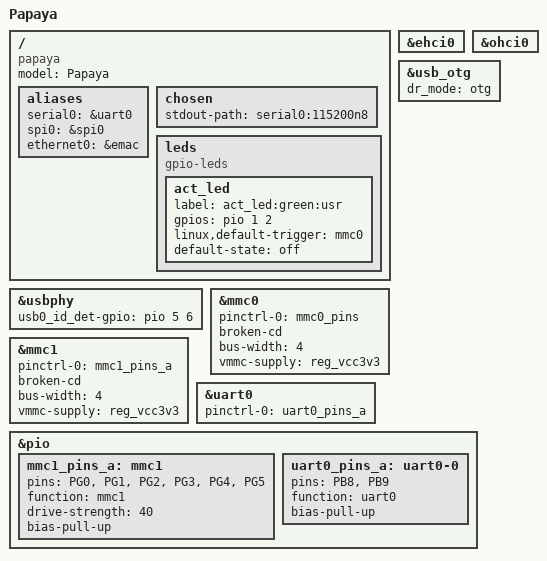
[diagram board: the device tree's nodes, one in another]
/dts-v1/;
#include "sun8i-v3s.dtsi"
#include "sunxi-common-regulators.dtsi"
#include <dt-bindings/input/input.h>
/ {

	model = "Papaya";
	compatible = "papaya", "allwinner,sun8i-v3s";
	
	aliases {
		serial0 = &uart0;
		spi0 = &spi0;
		ethernet0 = &emac;
		
	};
	chosen {
		stdout-path = "serial0:115200n8";
		};

	leds {
	compatible = "gpio-leds";
	act_led {
		label = "act_led:green:usr";
		gpios = <&pio 1 2 GPIO_ACTIVE_HIGH>; /* PB2 */
		linux,default-trigger = "mmc0";
		default-state = "off";
	};
	};
};


&ehci0 {
        status = "okay";
}; 

&ohci0 {
        status = "okay";
}; 

&usb_otg {
	dr_mode = "otg";
	status = "okay";
};

&usbphy {
	usb0_id_det-gpio = <&pio 5 6 GPIO_ACTIVE_HIGH>;
	status = "okay";
};

&mmc0 {
	pinctrl-0 = <&mmc0_pins>;
	pinctrl-names = "default";
	broken-cd;
	bus-width = <4>;
	vmmc-supply = <&reg_vcc3v3>;
	status = "okay";
};
&mmc1 {
	pinctrl-0 = <&mmc1_pins_a>;
	pinctrl-names = "default";
	broken-cd;
	bus-width = <4>;
	vmmc-supply = <&reg_vcc3v3>;
	status = "okay";
};

&uart0 { pinctrl-0 = <&uart0_pins_a>;pinctrl-names = "default";status = "okay"; };
	
&pio {
		mmc1_pins_a: mmc1 {
			pins = "PG0", "PG1", "PG2", "PG3", "PG4", "PG5";
			function = "mmc1";
			drive-strength = <40>;
			bias-pull-up;
		};
	uart0_pins_a: uart0-0 { pins = "PB8", "PB9";function = "uart0";bias-pull-up; };
};

